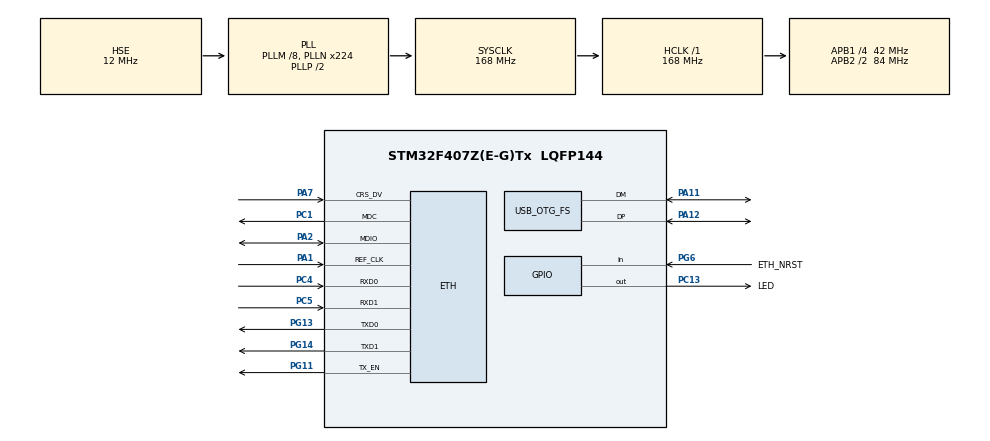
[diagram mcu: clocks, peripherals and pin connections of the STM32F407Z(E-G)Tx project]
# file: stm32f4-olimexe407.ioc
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ETH.MACAddr=00\:80\:E1\:00\:00\:01
ETH.MediaInterface=ETH_MEDIA_INTERFACE_RMII
ETH.PhyAddress=0
FREERTOS.Tasks01=defaultTask,24,128,StartDefaultTask,Default,NULL,Dynamic,NULL,NULL
LWIP.CMSIS_VERSION-Enabled=1
LWIP.LWIP_DNS=0
LWIP.Version=v2.1.2_Cube
Mcu.Family=STM32F4
Mcu.Name=STM32F407Z(E-G)Tx
Mcu.Package=LQFP144
Mcu.UserConstants=LWIP_NETIF_HOSTNAME,1
NVIC.ETH_IRQn=true\:5\:0\:true\:false\:true\:true\:false\:true
NVIC.OTG_FS_IRQn=true\:4\:0\:true\:false\:true\:true\:false\:true
NVIC.PriorityGroup=NVIC_PRIORITYGROUP_4
NVIC.TIM1_TRG_COM_TIM11_IRQn=true\:0\:0\:false\:false\:true\:false\:false\:true
NVIC.TimeBase=TIM1_TRG_COM_TIM11_IRQn
NVIC.TimeBaseIP=TIM11
PA1.Mode=RMII
PA1.Signal=ETH_REF_CLK
PA11.Mode=Device_Only
PA11.Signal=USB_OTG_FS_DM
PA12.Mode=Device_Only
PA12.Signal=USB_OTG_FS_DP
PA2.Mode=RMII
PA2.Signal=ETH_MDIO
PA7.Mode=RMII
PA7.Signal=ETH_CRS_DV
PC1.Mode=RMII
PC1.Signal=ETH_MDC
PC13-ANTI_TAMP.GPIO_Label=LED
PC13-ANTI_TAMP.GPIO_ModeDefaultOutputPP=GPIO_MODE_OUTPUT_PP
PC13-ANTI_TAMP.Signal=GPIO_Output
PC14-OSC32_IN.Mode=LSE-External-Oscillator
PC14-OSC32_IN.Signal=RCC_OSC32_IN
PC15-OSC32_OUT.Mode=LSE-External-Oscillator
PC15-OSC32_OUT.Signal=RCC_OSC32_OUT
PC4.Mode=RMII
PC4.Signal=ETH_RXD0
PC5.Mode=RMII
PC5.Signal=ETH_RXD1
PG11.Mode=RMII
PG11.Signal=ETH_TX_EN
PG13.Mode=RMII
PG13.Signal=ETH_TXD0
PG14.Mode=RMII
PG14.Signal=ETH_TXD1
PG6.GPIO_Label=ETH_NRST
PG6.Signal=GPIO_Input
PH0-OSC_IN.Mode=HSE-External-Oscillator
PH0-OSC_IN.Signal=RCC_OSC_IN
PH1-OSC_OUT.Mode=HSE-External-Oscillator
PH1-OSC_OUT.Signal=RCC_OSC_OUT
ProjectManager.HeapSize=0x200
ProjectManager.StackSize=0x400
ProjectManager.TargetToolchain=STM32CubeIDE
RCC.48MHZClocksFreq_Value=48000000
RCC.AHBFreq_Value=168000000
RCC.APB1CLKDivider=RCC_HCLK_DIV4
RCC.APB1Freq_Value=42000000
RCC.APB1TimFreq_Value=84000000
RCC.APB2CLKDivider=RCC_HCLK_DIV2
RCC.APB2Freq_Value=84000000
RCC.APB2TimFreq_Value=168000000
RCC.CortexFreq_Value=168000000
RCC.HCLKFreq_Value=168000000
RCC.HSE_VALUE=12000000
RCC.HSI_VALUE=16000000
RCC.PLLM=8
RCC.PLLN=224
RCC.PLLQ=7
RCC.SYSCLKFreq_VALUE=168000000
RCC.SYSCLKSource=RCC_SYSCLKSOURCE_PLLCLK
RCC.VCOOutputFreq_Value=336000000
USB_DEVICE.CLASS_NAME_FS=CDC
USB_DEVICE.VirtualMode-CDC_FS=Cdc
USB_DEVICE.VirtualModeFS=Cdc_FS
USB_OTG_FS.VirtualMode=Device_Only
VP_CRC_VS_CRC.Mode=CRC_Activate
VP_FREERTOS_VS_CMSIS_V2.Mode=CMSIS_V2
VP_LWIP_VS_Enabled.Mode=Enabled
VP_SYS_VS_tim11.Mode=TIM11
VP_USB_DEVICE_VS_USB_DEVICE_CDC_FS.Mode=CDC_FS
board=custom

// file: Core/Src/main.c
/* USER CODE BEGIN Header */
/**
  ******************************************************************************
  * @file           : main.c
  * @brief          : Main program body
  ******************************************************************************
  * @attention
  *
  * <h2><center>&copy; Copyright (c) 2020 STMicroelectronics.
  * All rights reserved.</center></h2>
  *
  * This software component is licensed by ST under BSD 3-Clause license,
  * the "License"; You may not use this file except in compliance with the
  * License. You may obtain a copy of the License at:
  *                        opensource.org/licenses/BSD-3-Clause
  *
  ******************************************************************************
  */
/* USER CODE END Header */
#include "main.h"
#include "cmsis_os.h"
#include "lwip.h"
#include "usb_device.h"

CRC_HandleTypeDef hcrc;

/* Definitions for defaultTask */
osThreadId_t defaultTaskHandle;
const osThreadAttr_t defaultTask_attributes = {
  .name = "defaultTask",
  .priority = (osPriority_t) osPriorityNormal,
  .stack_size = 128 * 4
};

void SystemClock_Config(void);
static void MX_GPIO_Init(void);
static void MX_CRC_Init(void);
void StartDefaultTask(void *argument);

int main(void)
{

  /* MCU Configuration--------------------------------------------------------*/

  /* Reset of all peripherals, Initializes the Flash interface and the Systick. */
  HAL_Init();

  /* Configure the system clock */
  SystemClock_Config();

  /* Initialize all configured peripherals */
  MX_GPIO_Init();
  MX_CRC_Init();

  /* Init scheduler */
  osKernelInitialize();

  /* Create the thread(s) */
  /* creation of defaultTask */
  defaultTaskHandle = osThreadNew(StartDefaultTask, NULL, &defaultTask_attributes);

  /* Start scheduler */
  osKernelStart();

  /* We should never get here as control is now taken by the scheduler */
  /* Infinite loop */
  while (1)
  {

  }
}

void SystemClock_Config(void)
{
  RCC_OscInitTypeDef RCC_OscInitStruct = {0};
  RCC_ClkInitTypeDef RCC_ClkInitStruct = {0};

  /** Configure the main internal regulator output voltage
  */
  __HAL_RCC_PWR_CLK_ENABLE();
  __HAL_PWR_VOLTAGESCALING_CONFIG(PWR_REGULATOR_VOLTAGE_SCALE1);
  /** Initializes the RCC Oscillators according to the specified parameters
  * in the RCC_OscInitTypeDef structure.
  */
  RCC_OscInitStruct.OscillatorType = RCC_OSCILLATORTYPE_HSE;
  RCC_OscInitStruct.HSEState = RCC_HSE_ON;
  RCC_OscInitStruct.PLL.PLLState = RCC_PLL_ON;
  RCC_OscInitStruct.PLL.PLLSource = RCC_PLLSOURCE_HSE;
  RCC_OscInitStruct.PLL.PLLM = 8;
  RCC_OscInitStruct.PLL.PLLN = 224;
  RCC_OscInitStruct.PLL.PLLP = RCC_PLLP_DIV2;
  RCC_OscInitStruct.PLL.PLLQ = 7;
  if (HAL_RCC_OscConfig(&RCC_OscInitStruct) != HAL_OK)
  {
    Error_Handler();
  }
  /** Initializes the CPU, AHB and APB buses clocks
  */
  RCC_ClkInitStruct.ClockType = RCC_CLOCKTYPE_HCLK|RCC_CLOCKTYPE_SYSCLK
                              |RCC_CLOCKTYPE_PCLK1|RCC_CLOCKTYPE_PCLK2;
  RCC_ClkInitStruct.SYSCLKSource = RCC_SYSCLKSOURCE_PLLCLK;
  RCC_ClkInitStruct.AHBCLKDivider = RCC_SYSCLK_DIV1;
  RCC_ClkInitStruct.APB1CLKDivider = RCC_HCLK_DIV4;
  RCC_ClkInitStruct.APB2CLKDivider = RCC_HCLK_DIV2;

  if (HAL_RCC_ClockConfig(&RCC_ClkInitStruct, FLASH_LATENCY_5) != HAL_OK)
  {
    Error_Handler();
  }
}

static void MX_CRC_Init(void)
{

  hcrc.Instance = CRC;
  if (HAL_CRC_Init(&hcrc) != HAL_OK)
  {
    Error_Handler();
  }

}

static void MX_GPIO_Init(void)
{
  GPIO_InitTypeDef GPIO_InitStruct = {0};

  /* GPIO Ports Clock Enable */
  __HAL_RCC_GPIOC_CLK_ENABLE();
  __HAL_RCC_GPIOH_CLK_ENABLE();
  __HAL_RCC_GPIOA_CLK_ENABLE();
  __HAL_RCC_GPIOG_CLK_ENABLE();

  /*Configure GPIO pin Output Level */
  HAL_GPIO_WritePin(LED_GPIO_Port, LED_Pin, GPIO_PIN_RESET);

  /*Configure GPIO pin : LED_Pin */
  GPIO_InitStruct.Pin = LED_Pin;
  GPIO_InitStruct.Mode = GPIO_MODE_OUTPUT_PP;
  GPIO_InitStruct.Pull = GPIO_NOPULL;
  GPIO_InitStruct.Speed = GPIO_SPEED_FREQ_LOW;
  HAL_GPIO_Init(LED_GPIO_Port, &GPIO_InitStruct);

  /*Configure GPIO pin : ETH_NRST_Pin */
  GPIO_InitStruct.Pin = ETH_NRST_Pin;
  GPIO_InitStruct.Mode = GPIO_MODE_INPUT;
  GPIO_InitStruct.Pull = GPIO_NOPULL;
  HAL_GPIO_Init(ETH_NRST_GPIO_Port, &GPIO_InitStruct);

}

void StartDefaultTask(void *argument)
{
  /* init code for LWIP */
  MX_LWIP_Init();

  /* init code for USB_DEVICE */
  MX_USB_DEVICE_Init();
  /* USER CODE BEGIN 5 */
  /* Infinite loop */
  uint8_t buffer[]="hello from stm";
  for(;;)
  {
	 // HAL_UART_Transmit(&huart6, buffer, sizeof(buffer), HAL_MAX_DELAY);
	  //HAL_GPIO_TogglePin(LED_GPIO_Port, LED_Pin);
      //osDelay(500);
  }
  /* USER CODE END 5 */
}

void HAL_TIM_PeriodElapsedCallback(TIM_HandleTypeDef *htim)
{
  if (htim->Instance == TIM11) {
    HAL_IncTick();
  }
}

void Error_Handler(void)
{
}

/************************ (C) COPYRIGHT STMicroelectronics *****END OF FILE****/
